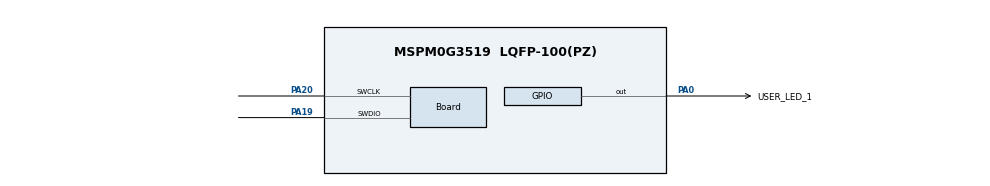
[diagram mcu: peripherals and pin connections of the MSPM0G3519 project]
//@cliArgs --device "MSPM0G351X" --package "LQFP-100(PZ)" --part "Default"
//@v2CliArgs --device "MSPM0G3519" --package "LQFP-100(PZ)"
// @cliArgs --board /ti/boards/LP_MSPM0G3519 --rtos nortos

/**
 * Import the modules used in this configuration.
 */
const GPIO   = scripting.addModule("/ti/driverlib/GPIO", {}, false);
const GPIO1  = GPIO.addInstance();
const GPIO2  = GPIO.addInstance();
const SYSCTL = scripting.addModule("/ti/driverlib/SYSCTL");

/**
 * Write custom configuration values to the imported modules.
 */
GPIO1.$name                          = "GPIO_LEDS";
GPIO1.associatedPins[0].$name        = "USER_LED_1";
GPIO1.associatedPins[0].assignedPort = "PORTA";
GPIO1.associatedPins[0].assignedPin  = "0";
GPIO1.associatedPins[0].initialValue = "SET";
GPIO1.associatedPins[0].pin.$assign  = "PA0";

const Board                       = scripting.addModule("/ti/driverlib/Board", {}, false);
Board.peripheral.$assign          = "DEBUGSS";
Board.peripheral.swclkPin.$assign = "PA20";
Board.peripheral.swdioPin.$assign = "PA19";

GPIO2.$name                              = "GPIO_SWITCHES";
GPIO2.associatedPins[0].assignedPort     = "PORTB";
GPIO2.associatedPins[0].$name            = "USER_SWITCH_1";
GPIO2.associatedPins[0].direction        = "INPUT";
GPIO2.associatedPins[0].assignedPin      = "3";
GPIO2.associatedPins[0].internalResistor = "PULL_UP";

SYSCTL.forceDefaultClkConfig = true;
SYSCTL.clockTreeEn           = true;

const ProjectConfig              = scripting.addModule("/ti/project_config/ProjectConfig", {}, false);
ProjectConfig.migrationCondition = true;
